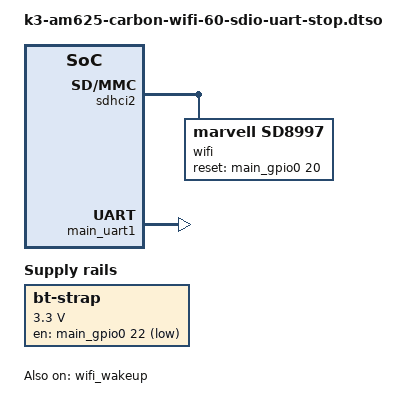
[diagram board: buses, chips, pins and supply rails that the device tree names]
// SPDX-License-Identifier: (GPL-2.0+ OR MIT)
/*
 * SDIO Summit/Sterling 60 in SDIO-UART mode 
 * Support stop-shutdown mode - radio de-powered on link down
 *
 * Copyright (C) 2024 Ezurio LLC
 */

/dts-v1/;
/plugin/;

#include <dt-bindings/gpio/gpio.h>

&{/} {
	regulator-bt-strap {
		compatible = "regulator-fixed";
		regulator-name = "bt-strap";
		regulator-min-microvolt = <3300000>;
		regulator-max-microvolt = <3300000>;

		pinctrl-names = "default";
		pinctrl-0 = <&main_bt_en_pins_default>;
		gpios = <&main_gpio0 22 GPIO_ACTIVE_HIGH>;
		enable-active-low; /* SDIO-UART mode */
		regulator-always-on;
	};
};

&sdhci2 {
	pinctrl-0 = <&main_mmc2_pins_default>, <&main_wifi_en_default>;

	status = "okay";

	wifi {
		compatible = "marvell,sd8997";
		reset-gpios = <&main_gpio0 20 GPIO_ACTIVE_HIGH>;
		remove-power-on-link-down;
		fwtype = "sdio-uart";
	};
};

&main_uart1 {
	status = "okay";
};

&wifi_wakeup {
	status = "okay";
};
